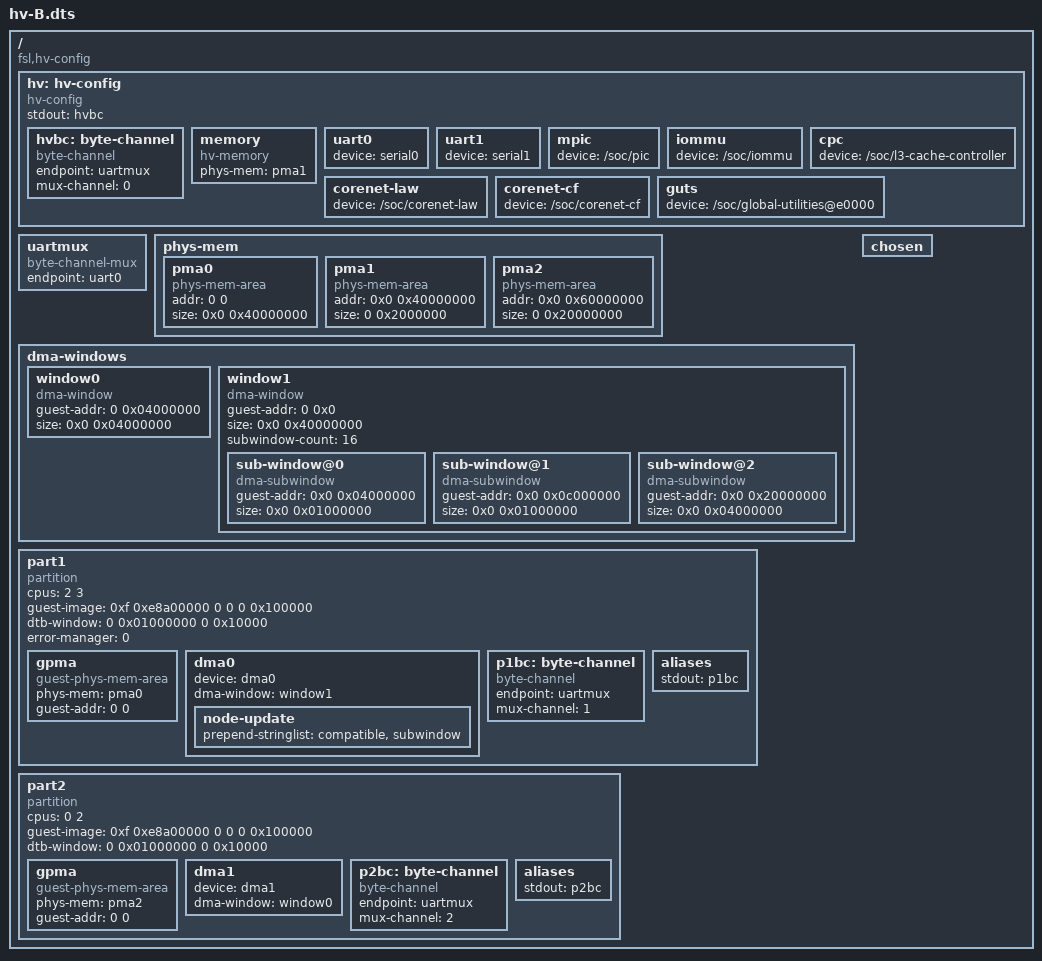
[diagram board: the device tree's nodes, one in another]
/*
 * Copyright (C) 2009,2010 Freescale Semiconductor, Inc.
 *
 * Redistribution and use in source and binary forms, with or without
 * modification, are permitted provided that the following conditions
 * are met:
 * 1. Redistributions of source code must retain the above copyright
 *    notice, this list of conditions and the following disclaimer.
 * 2. Redistributions in binary form must reproduce the above copyright
 *    notice, this list of conditions and the following disclaimer in the
 *    documentation and/or other materials provided with the distribution.
 *
 * THIS SOFTWARE IS PROVIDED BY THE AUTHOR "AS IS" AND ANY EXPRESS OR
 * IMPLIED WARRANTIES, INCLUDING, BUT NOT LIMITED TO, THE IMPLIED WARRANTIES
 * OF MERCHANTABILITY AND FITNESS FOR A PARTICULAR PURPOSE ARE DISCLAIMED.  IN
 * NO EVENT SHALL THE AUTHOR BE LIABLE FOR ANY DIRECT, INDIRECT, INCIDENTAL,
 * SPECIAL, EXEMPLARY, OR CONSEQUENTIAL DAMAGES (INCLUDING, BUT NOT LIMITED
 * TO, PROCUREMENT OF SUBSTITUTE GOODS OR SERVICES; LOSS OF USE, DATA, OR
 * PROFITS; OR BUSINESS INTERRUPTION) HOWEVER CAUSED AND ON ANY THEORY OF
 * LIABILITY, WHETHER IN CONTRACT, STRICT LIABILITY, OR TORT (INCLUDING
 * NEGLIGENCE OR OTHERWISE) ARISING IN ANY WAY OUT OF THE USE OF THIS
 * SOFTWARE, EVEN IF ADVISED OF THE POSSIBILITY OF SUCH DAMAGE.
 */

/dts-v1/;

/ {
	compatible = "fsl,hv-config";

	// =====================================================
	// Hypervisor Config
	// =====================================================
	hv: hv-config {
		compatible = "hv-config";
		stdout = <&hvbc>;

		hvbc: byte-channel {
			compatible = "byte-channel";
			endpoint = <&uartmux>;
			mux-channel = <0>;
		};

		memory {
			compatible = "hv-memory";
			phys-mem = <&pma1>;
		};

		uart0: uart0 {
			device = "serial0";
		};

		uart1: uart1 {
			device = "serial1";
		};

		mpic {
			device = "/soc/pic";
		};

		iommu {
			device = "/soc/iommu";
		};

		cpc {
			device = "/soc/l3-cache-controller";
		};

		corenet-law {
			device = "/soc/corenet-law";
		};

		corenet-cf {
			device = "/soc/corenet-cf";
		};

		guts {
			device = "/soc/global-utilities@e0000";
		};
	};

	uartmux: uartmux {
		compatible = "byte-channel-mux";
		endpoint = <&uart0>;
	};

	// =====================================================
	// Physical Memory Areas
	// =====================================================
	phys-mem {
		pma0: pma0 {
			compatible = "phys-mem-area";
			addr = <0 0>;
			size = <0x0 0x40000000>;
		};

		pma1: pma1 {
			compatible = "phys-mem-area";
			addr = <0x0 0x40000000>;
			size = <0 0x2000000>;
		};

		pma2: pma2 {
			compatible = "phys-mem-area";
			addr = <0x0 0x60000000>;
			size = <0 0x20000000>;
		};
	};

	dma-windows {
		window0: window0 {
			compatible = "dma-window";
			guest-addr = <0 0x04000000>;
			size = <0x0 0x04000000>; // 64M
		};

		window1: window1 {
			compatible = "dma-window";
			guest-addr = <0 0x0>;
			size = <0x0 0x40000000>; // 1G
			subwindow-count = <16>;
			sub-window@0 {
				compatible = "dma-subwindow";
				guest-addr = <0x0 0x04000000>;
				size = <0x0 0x01000000>; // 16M
			};
			sub-window@1 {
				compatible = "dma-subwindow";
				guest-addr = <0x0 0x0c000000>;
				size = <0x0 0x01000000>; // 16M
			};
			sub-window@2 {
				compatible = "dma-subwindow";
				guest-addr = <0x0 0x20000000>;
				size = <0x0 0x04000000>;
			};
		};
	};

	// =====================================================
	// Partition 1
	// =====================================================
	part1 {
		compatible = "partition";
		cpus = <2 3>;
		guest-image = <0xf 0xe8a00000 0 0 0 0x100000>;
		dtb-window = <0 0x01000000 0 0x10000>;
		error-manager = <0>;

		gpma {
			compatible = "guest-phys-mem-area";
			phys-mem = <&pma0>;
			guest-addr = <0 0>;
		};

		dma0: dma0 {
			device = "dma0";
			dma-window = <&window1>;
			node-update {
				prepend-stringlist = "compatible", "subwindow";
			};
		};

		p1bc: byte-channel {
			compatible = "byte-channel";
			endpoint = <&uartmux>;
			mux-channel = <1>;
		};

		aliases {
			stdout = <&p1bc>;
		};
	};

	// =====================================================
	// Partition 2
	// =====================================================
	part2 {
		compatible = "partition";
		cpus = <0 2>;
		guest-image = <0xf 0xe8a00000 0 0 0 0x100000>;
		dtb-window = <0 0x01000000 0 0x10000>;

		gpma {
			compatible = "guest-phys-mem-area";
			phys-mem = <&pma2>;
			guest-addr = <0 0>;
		};

		dma1: dma1 {
			device = "dma1";
			dma-window = <&window0>;
		};

		p2bc: byte-channel {
			compatible = "byte-channel";
			endpoint = <&uartmux>;
			mux-channel = <2>;
		};

		aliases {
			stdout = <&p2bc>;
		};
	};
	chosen {
	};
};
